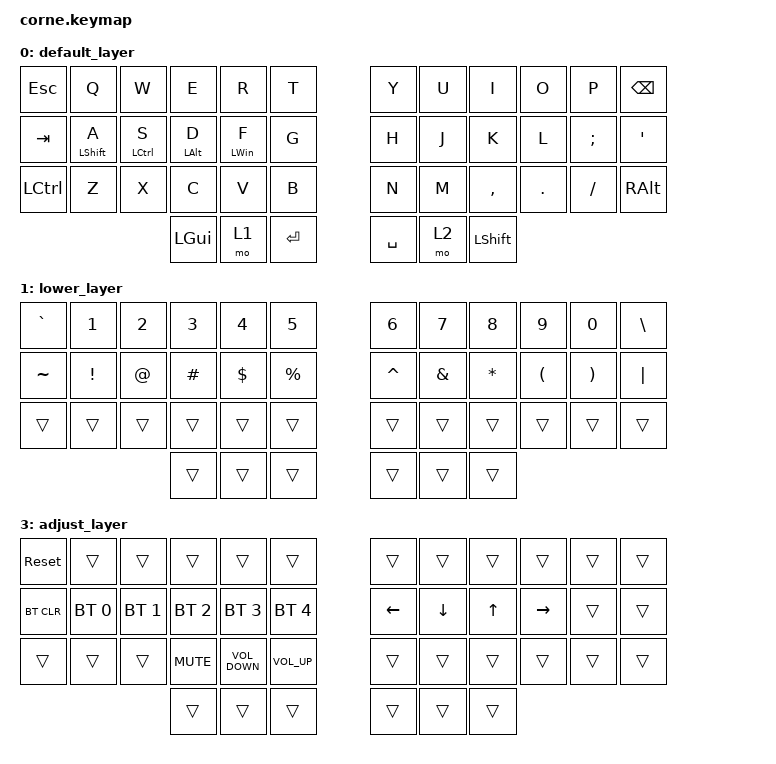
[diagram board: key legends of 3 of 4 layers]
/*
 * Copyright (c) 2020 The ZMK Contributors
 *
 * SPDX-License-Identifier: MIT
 * To use home rows - &hm LSHFT F
 */

#include <behaviors.dtsi>
#include <dt-bindings/zmk/bt.h>
#include <dt-bindings/zmk/keys.h>

#define QWERTY 0
#define NUMB 1
#define NAVI 2
#define ADJUST 3

/ {
    behaviors {
        hm: homerow_mods {
            compatible = "zmk,behavior-hold-tap";
            label = "HOMEROW_MODS";
            #binding-cells = <2>;
            tapping-term-ms = <150>;
            quick_tap_ms = <0>;
            flavor = "tap-preferred";
            bindings = <&kp>, <&kp>;
        };
    };

    keymap {
        compatible = "zmk,keymap";

        default_layer {
            // .--------------------------------------------------------------.       .-----------------------------------------------------------.
            // |   ESC        |    Q    |    W   |   E    |    R    |    T    |       |   Y   |    U    |    I    |    O    |     P    |   BACK   |
            // |--------------+---------+--------+--------+---------+---------|       |-------+---------+---------+---------+----------+----------|
            // |   TAB        |    A    |    S   |   D    |    F    |    G    |       |   H   |    J    |    K    |    L    |     ;    |     '    |
            // |--------------+---------+--------+--------+---------+---------|       |-------+---------+---------+---------+----------+----------|
            // |   SHFT       |    Z    |    X   |   C    |    V    |    B    |       |   N   |    M    |    ,    |    .    |     /    |   ALT    |
            // '---------------------------------+--------+---------+---------+       |-------+---------+---------+-------------------------------'
            //                                   |  GUI   |   MO1   |   ENT   |       |  SPC  |   BKSP  | LSHIFT  |
            //                                   '--------+---------+---------'       '-------+---------+---------'

            bindings = <
&kp ESC    &kp Q             &kp W        &kp E           &kp R       &kp T        &kp Y      &kp U  &kp I       &kp O    &kp P     &kp BACKSPACE
&kp TAB    &hm LEFT_SHIFT A  &hm LCTRL S  &hm LEFT_ALT D  &hm LWIN F  &kp G        &kp H      &kp J  &kp K       &kp L    &kp SEMI  &kp SQT
&kp LCTRL  &kp Z             &kp X        &kp C           &kp V       &kp B        &kp N      &kp M  &kp COMMA   &kp DOT  &kp FSLH  &kp RALT
                                          &kp LGUI        &mo 1       &kp ENTER    &kp SPACE  &mo 2  &kp LSHIFT
            >;
        };

        lower_layer {
            // .--------------------------------------------------------------.        .------------------------------------------------------------------.
            // |   ESC        |    1    |    2   |   3    |    4    |    5    |        |   6     |     7   |     8    |    9     |     0    |             |
            // |--------------+---------+--------+--------+---------+---------|        |---------+---------+----------+----------+----------+-------------|
            // |   CAPS       |         |        |        |         |         |        |   LEFT  |   DOWN  |    UP    |  RIGHT   |          |             |
            // |--------------+---------+--------+--------+---------+---------|        |---------+---------+----------+----------+----------+-------------|
            // |   SHFT       |         |        |        |         |         |        |         |         |          |          |          |             |
            // '---------------------------------+--------+---------+---------+        |---------+---------+----------+-----------------------------------'
            //                                   |  GUI   |         |   MO3   |        |         |         |          |
            //                                   '--------+---------+---------'        '---------+---------+----------'

            bindings = <
&kp GRAVE  &kp N1    &kp N2  &kp N3    &kp N4      &kp N5         &kp N6     &kp N7         &kp N8    &kp N9                &kp N0                 &kp BACKSLASH
&kp TILDE  &kp EXCL  &kp AT  &kp HASH  &kp DOLLAR  &kp PERCENT    &kp CARET  &kp AMPERSAND  &kp STAR  &kp LEFT_PARENTHESIS  &kp RIGHT_PARENTHESIS  &kp PIPE
&trans     &trans    &trans  &trans    &trans      &trans         &trans     &trans         &trans    &trans                &trans                 &trans
                             &trans    &trans      &trans         &trans     &trans         &trans
            >;
        };

        raise_layer {
            // .----------------------------------------------------------------.       .-----------------------------------------------------------------.
            // |                |       |        |        |          |          |       |         |     _    |    +    |    {    |     }    |     DEL     |
            // |----------------+-------+--------+--------+----------+----------|       |---------+----------+---------+---------+----------+-------------|
            // |                |       |  LEFT  |  DOWN  |   RIGHT  |   END    |       |         |     -    |    =    |    [    |     ]    |             |
            // |----------------+-------+--------+--------+----------+----------|       |---------+----------+---------+---------+----------+-------------|
            // |                |       |        |        |          |          |       |         |          |         |         |          |             |
            // '---------------------------------+--------+----------+----------+       |---------+----------+---------+----------------------------------'
            //                                   |  GUI   |   MO3    |          |       |         |          |         |
            //                                   '--------+----------+----------'       '---------+----------+---------'

            bindings = <
&trans  &trans  &trans  &trans  &trans  &trans    &trans  &kp UNDERSCORE  &kp PLUS   &kp LEFT_BRACE    &kp RIGHT_BRACE    &kp DELETE
&trans  &trans  &trans  &trans  &trans  &trans    &trans  &kp MINUS       &kp EQUAL  &kp LEFT_BRACKET  &kp RIGHT_BRACKET  &trans
&trans  &trans  &trans  &trans  &trans  &trans    &trans  &trans          &trans     &trans            &trans             &trans
                        &trans  &trans  &trans    &trans  &trans
            >;
        };

        adjust_layer {
            // .--------------------------------------------------------------------------------------.         .--------------------------------------------------------------.
            // |          |            |             |             |                  |               |         |        |        |         |         |          |             |
            // |----------+------------+-------------+-------------+------------------+---------------|         |--------+--------+---------+---------+----------+-------------|
            // |  BTCLR   | BT0        |  BT2        |     BT3     |        BT4       |      BT5      |         |        |        |         |         |          |             |
            // |----------+------------+-------------+-------------+------------------+---------------|         |--------+--------+---------+---------+----------+-------------|
            // |          |            |             |     MUTE    |        VOL-      |      VOL+     |         |        |        |         |         |          |             |
            // '-------------------------------------+-------------+------------------+---------------+         |--------+--------+---------+----------------------------------'
            //                                       |             |                  |               |         |        |        |         |
            //                                       '-------------+------------------+---------------'         '--------+--------+---------'

            bindings = <
&sys_reset  &trans        &trans        &trans        &trans             &trans             &trans          &trans          &trans        &trans     &trans  &trans
&bt BT_CLR  &bt BT_SEL 0  &bt BT_SEL 1  &bt BT_SEL 2  &bt BT_SEL 3       &bt BT_SEL 4       &kp LEFT_ARROW  &kp DOWN_ARROW  &kp UP_ARROW  &kp RIGHT  &trans  &trans
&trans      &trans        &trans        &kp C_MUTE    &kp C_VOLUME_DOWN  &kp C_VOLUME_UP    &trans          &trans          &trans        &trans     &trans  &trans
                                        &trans        &trans             &trans             &trans          &trans          &trans
            >;
        };
    };
};
